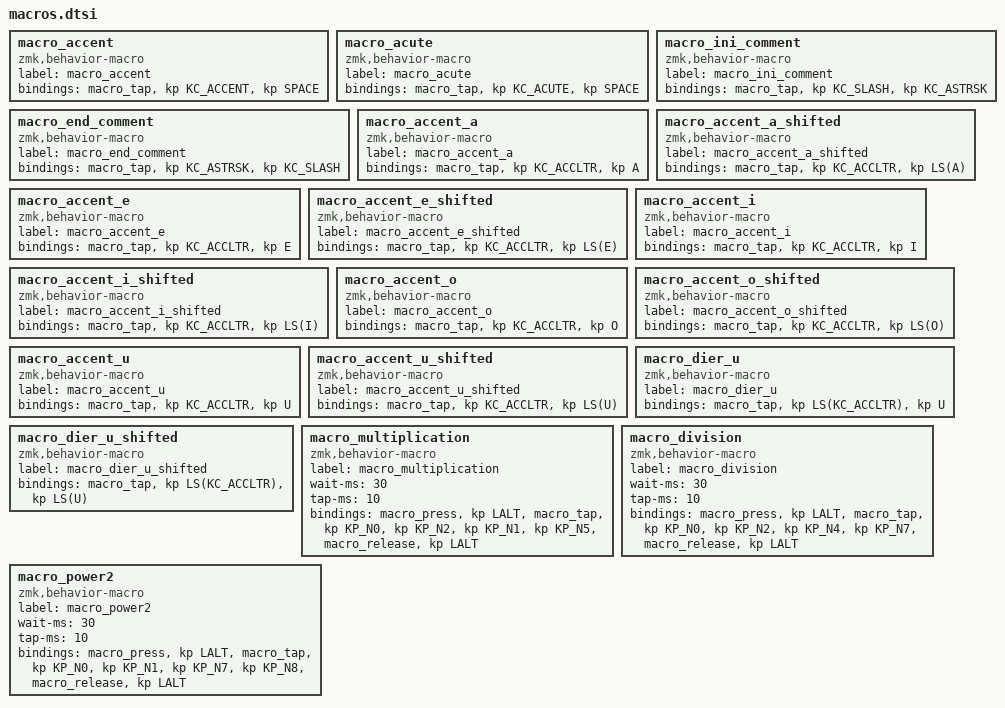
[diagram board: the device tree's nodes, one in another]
#include "keycodes.h"

macro_accent: macro_accent {                    //  ` + SPACE → ^ (with shift)
    label = "macro_accent"; compatible = "zmk,behavior-macro";
    #binding-cells = <0>; bindings = <&macro_tap &kp KC_ACCENT &kp SPACE>;
};
macro_acute: macro_acute {                    //  ^ (with shift) + SPACE
    label = "macro_acute"; compatible = "zmk,behavior-macro";
    #binding-cells = <0>; bindings = <&macro_tap &kp KC_ACUTE &kp SPACE>;
};


macro_ini_comment: macro_ini_comment {                    //  
    label = "macro_ini_comment"; compatible = "zmk,behavior-macro";
    #binding-cells = <0>; bindings = <&macro_tap &kp KC_SLASH &kp KC_ASTRSK>;
};
macro_end_comment: macro_end_comment {                    //  
    label = "macro_end_comment"; compatible = "zmk,behavior-macro";
    #binding-cells = <0>; bindings = <&macro_tap &kp KC_ASTRSK &kp KC_SLASH>;
};


macro_accent_a: macro_accent_a {                    //    a → á
    label = "macro_accent_a"; compatible = "zmk,behavior-macro";
    #binding-cells = <0>; bindings = <&macro_tap &kp KC_ACCLTR &kp A>;
};
macro_accent_a_shifted: macro_accent_a_shifted {                    //    A → Á
    label = "macro_accent_a_shifted"; compatible = "zmk,behavior-macro";
    #binding-cells = <0>; bindings = <&macro_tap &kp KC_ACCLTR &kp LS(A)>;
};
macro_accent_e: macro_accent_e {                    //    e → é
    label = "macro_accent_e"; compatible = "zmk,behavior-macro";
    #binding-cells = <0>; bindings = <&macro_tap &kp KC_ACCLTR &kp E>;
};
macro_accent_e_shifted: macro_accent_e_shifted {                    //    E → É
    label = "macro_accent_e_shifted"; compatible = "zmk,behavior-macro";
    #binding-cells = <0>; bindings = <&macro_tap &kp KC_ACCLTR &kp LS(E)>;
};
macro_accent_i: macro_accent_i {                    //    i → í
    label = "macro_accent_i"; compatible = "zmk,behavior-macro";
    #binding-cells = <0>; bindings = <&macro_tap &kp KC_ACCLTR &kp I>;
};
macro_accent_i_shifted: macro_accent_i_shifted {                    //    I → Í
    label = "macro_accent_i_shifted"; compatible = "zmk,behavior-macro";
    #binding-cells = <0>; bindings = <&macro_tap &kp KC_ACCLTR &kp LS(I)>;
};
macro_accent_o: macro_accent_o {                    //    o → ó
    label = "macro_accent_o"; compatible = "zmk,behavior-macro";
    #binding-cells = <0>; bindings = <&macro_tap &kp KC_ACCLTR &kp O>;
};
macro_accent_o_shifted: macro_accent_o_shifted {                    //    O → Ó
    label = "macro_accent_o_shifted"; compatible = "zmk,behavior-macro";
    #binding-cells = <0>; bindings = <&macro_tap &kp KC_ACCLTR &kp LS(O)>;
};  //////////////////////////////////////
macro_accent_u: macro_accent_u {                    //    u → ú
    label = "macro_accent_u"; compatible = "zmk,behavior-macro";
    #binding-cells = <0>; bindings = <&macro_tap &kp KC_ACCLTR &kp U>;
};
macro_accent_u_shifted: macro_accent_u_shifted {                    //    U → Ú
    label = "macro_accent_u_shifted"; compatible = "zmk,behavior-macro";
    #binding-cells = <0>; bindings = <&macro_tap &kp KC_ACCLTR &kp LS(U)>;
};
macro_dier_u: macro_dier_u {                    //    u → ü
    label = "macro_dier_u"; compatible = "zmk,behavior-macro";
    #binding-cells = <0>; bindings = <&macro_tap &kp LS(KC_ACCLTR) &kp U>;
};
macro_dier_u_shifted: macro_dier_u_shifted {                    //    U → Ü
    label = "macro_dier_u_shifted"; compatible = "zmk,behavior-macro";
    #binding-cells = <0>; bindings = <&macro_tap &kp LS(KC_ACCLTR) &kp LS(U)>;
};



macro_multiplication: macro_multiplication {                    // 0215 ×
    label = "macro_multiplication"; compatible = "zmk,behavior-macro"; wait-ms = <30>; tap-ms = <10>;
    #binding-cells = <0>; bindings = <&macro_press &kp LALT>, <&macro_tap &kp KP_N0 &kp KP_N2 &kp KP_N1 &kp KP_N5>, <&macro_release &kp LALT>;  // without &macro_tap it seems to assume the previous &macro_press, which leads to the keyboard freezing
};
macro_division: macro_division {                    // 0247 ÷
    label = "macro_division"; compatible = "zmk,behavior-macro"; wait-ms = <30>; tap-ms = <10>;
    #binding-cells = <0>; bindings = <&macro_press &kp LALT>, <&macro_tap &kp KP_N0 &kp KP_N2 &kp KP_N4 &kp KP_N7>, <&macro_release &kp LALT>;
};
macro_power2: macro_power2 {                    // 0178 ²
    label = "macro_power2"; compatible = "zmk,behavior-macro"; wait-ms = <30>; tap-ms = <10>;
    #binding-cells = <0>; bindings = <&macro_press &kp LALT>, <&macro_tap &kp KP_N0 &kp KP_N1 &kp KP_N7 &kp KP_N8>, <&macro_release &kp LALT>;
};


//ZMK_MACRO(macro_multiplication, wait-ms = <60>; tap-ms = <100>;                                                  // 0215 ×
//  bindings = <&macro_press &kp LALT>, <&macro_tap &kp KP_N0 &kp KP_N2 &kp KP_N1 &kp KP_N5>, <&macro_release &kp LALT>;)
//ZMK_MACRO(macro_division, wait-ms = <60>; tap-ms = <60>;                                                  // 0247 ÷
//  bindings = <&macro_press &kp LALT>, <&macro_tap &kp KP_N0 &kp KP_N2 &kp KP_N4 &kp KP_N7>, <&macro_release &kp LALT>;)
//ZMK_MACRO(macro_power2, wait-ms = <60>; tap-ms = <60>;                                                   // 0178 ²
//  bindings = <&macro_press &kp LALT>, <&macro_tap &kp KP_N0 &kp KP_N1 &kp KP_N7 &kp KP_N8>, <&macro_release &kp LALT>;)

